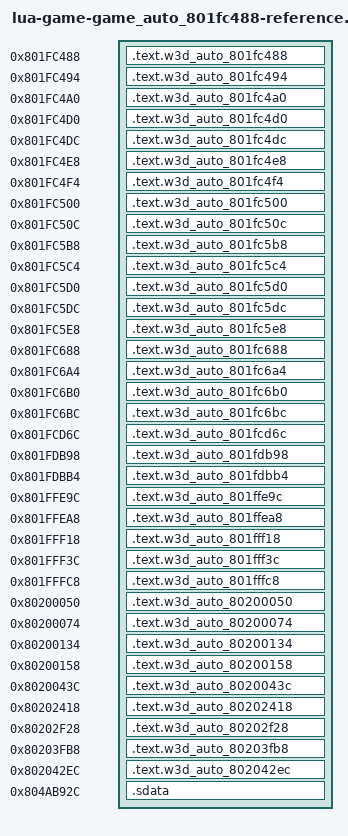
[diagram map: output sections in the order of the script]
/* Generated reference-only placements. All bodies are source-built. */
OUTPUT_FORMAT("elf32-powerpc")
OUTPUT_ARCH(powerpc)
ENTRY(w3d_auto_801fc488)
_SDA_BASE_ = 0x804b2540;
_SDA2_BASE_ = 0x804c2540;
fn_8016E698 = 0x8016e698;
fn_8020017C = 0x8020017c;
fn_802001A8 = 0x802001a8;
fn_802001D4 = 0x802001d4;
fn_80200460 = 0x80200460;
fn_8020430C = 0x8020430c;
fn_80204760 = 0x80204760;
fn_8035A3A8 = 0x8035a3a8;
SECTIONS {
  .text.w3d_auto_801fc488 0x801fc488 : { *(.text.w3d_auto_801fc488) }
  .text.w3d_auto_801fc494 0x801fc494 : { *(.text.w3d_auto_801fc494) }
  .text.w3d_auto_801fc4a0 0x801fc4a0 : { *(.text.w3d_auto_801fc4a0) }
  .text.w3d_auto_801fc4d0 0x801fc4d0 : { *(.text.w3d_auto_801fc4d0) }
  .text.w3d_auto_801fc4dc 0x801fc4dc : { *(.text.w3d_auto_801fc4dc) }
  .text.w3d_auto_801fc4e8 0x801fc4e8 : { *(.text.w3d_auto_801fc4e8) }
  .text.w3d_auto_801fc4f4 0x801fc4f4 : { *(.text.w3d_auto_801fc4f4) }
  .text.w3d_auto_801fc500 0x801fc500 : { *(.text.w3d_auto_801fc500) }
  .text.w3d_auto_801fc50c 0x801fc50c : { *(.text.w3d_auto_801fc50c) }
  .text.w3d_auto_801fc5b8 0x801fc5b8 : { *(.text.w3d_auto_801fc5b8) }
  .text.w3d_auto_801fc5c4 0x801fc5c4 : { *(.text.w3d_auto_801fc5c4) }
  .text.w3d_auto_801fc5d0 0x801fc5d0 : { *(.text.w3d_auto_801fc5d0) }
  .text.w3d_auto_801fc5dc 0x801fc5dc : { *(.text.w3d_auto_801fc5dc) }
  .text.w3d_auto_801fc5e8 0x801fc5e8 : { *(.text.w3d_auto_801fc5e8) }
  .text.w3d_auto_801fc688 0x801fc688 : { *(.text.w3d_auto_801fc688) }
  .text.w3d_auto_801fc6a4 0x801fc6a4 : { *(.text.w3d_auto_801fc6a4) }
  .text.w3d_auto_801fc6b0 0x801fc6b0 : { *(.text.w3d_auto_801fc6b0) }
  .text.w3d_auto_801fc6bc 0x801fc6bc : { *(.text.w3d_auto_801fc6bc) }
  .text.w3d_auto_801fcd6c 0x801fcd6c : { *(.text.w3d_auto_801fcd6c) }
  .text.w3d_auto_801fdb98 0x801fdb98 : { *(.text.w3d_auto_801fdb98) }
  .text.w3d_auto_801fdbb4 0x801fdbb4 : { *(.text.w3d_auto_801fdbb4) }
  .text.w3d_auto_801ffe9c 0x801ffe9c : { *(.text.w3d_auto_801ffe9c) }
  .text.w3d_auto_801ffea8 0x801ffea8 : { *(.text.w3d_auto_801ffea8) }
  .text.w3d_auto_801fff18 0x801fff18 : { *(.text.w3d_auto_801fff18) }
  .text.w3d_auto_801fff3c 0x801fff3c : { *(.text.w3d_auto_801fff3c) }
  .text.w3d_auto_801fffc8 0x801fffc8 : { *(.text.w3d_auto_801fffc8) }
  .text.w3d_auto_80200050 0x80200050 : { *(.text.w3d_auto_80200050) }
  .text.w3d_auto_80200074 0x80200074 : { *(.text.w3d_auto_80200074) }
  .text.w3d_auto_80200134 0x80200134 : { *(.text.w3d_auto_80200134) }
  .text.w3d_auto_80200158 0x80200158 : { *(.text.w3d_auto_80200158) }
  .text.w3d_auto_8020043c 0x8020043c : { *(.text.w3d_auto_8020043c) }
  .text.w3d_auto_80202418 0x80202418 : { *(.text.w3d_auto_80202418) }
  .text.w3d_auto_80202f28 0x80202f28 : { *(.text.w3d_auto_80202f28) }
  .text.w3d_auto_80203fb8 0x80203fb8 : { *(.text.w3d_auto_80203fb8) }
  .text.w3d_auto_802042ec 0x802042ec : { *(.text.w3d_auto_802042ec) }
  .sdata 0x804ab92c (NOLOAD) : {
    . = 0x0; lbl_804AB92C = .;
    . = 0x10; lbl_804AB93C = .;
    . += 1; }
  /DISCARD/ : { *(.text*) *(.rodata*) *(.data*) *(.bss*) *(.sdata*) *(.sbss*) *(.comment) }
}
